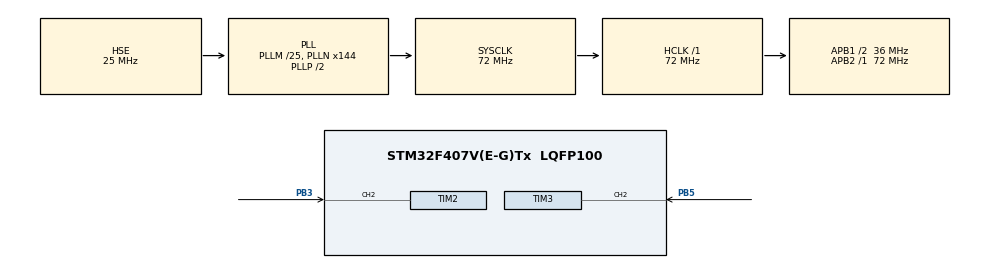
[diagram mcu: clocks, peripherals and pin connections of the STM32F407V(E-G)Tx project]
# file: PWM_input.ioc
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Mcu.Family=STM32F4
Mcu.Name=STM32F407V(E-G)Tx
Mcu.Package=LQFP100
NVIC.PriorityGroup=NVIC_PRIORITYGROUP_4
NVIC.TIM2_IRQn=true\:0\:0\:false\:false\:true\:true\:true
NVIC.TIM3_IRQn=true\:0\:0\:false\:false\:true\:true\:true
PB3.Signal=S_TIM2_CH2
PB5.Signal=S_TIM3_CH2
PH0-OSC_IN.Mode=HSE-External-Oscillator
PH0-OSC_IN.Signal=RCC_OSC_IN
PH1-OSC_OUT.Mode=HSE-External-Oscillator
PH1-OSC_OUT.Signal=RCC_OSC_OUT
ProjectManager.HeapSize=0x200
ProjectManager.StackSize=0x400
ProjectManager.TargetToolchain=MDK-ARM V5.27
RCC.48MHZClocksFreq_Value=36000000
RCC.AHBFreq_Value=72000000
RCC.APB1CLKDivider=RCC_HCLK_DIV2
RCC.APB1Freq_Value=36000000
RCC.APB1TimFreq_Value=72000000
RCC.APB2Freq_Value=72000000
RCC.APB2TimFreq_Value=72000000
RCC.CortexFreq_Value=72000000
RCC.HCLKFreq_Value=72000000
RCC.HSE_VALUE=25000000
RCC.HSI_VALUE=16000000
RCC.LSE_VALUE=32768
RCC.PLLM=25
RCC.PLLN=144
RCC.PLLSourceVirtual=RCC_PLLSOURCE_HSE
RCC.SYSCLKFreq_VALUE=72000000
RCC.SYSCLKSource=RCC_SYSCLKSOURCE_PLLCLK
RCC.VCOOutputFreq_Value=144000000
SH.S_TIM2_CH2.0=TIM2_CH2,Input_Capture2_from_TI2
SH.S_TIM2_CH2.1=TIM2_CH2,Input_Capture1_from_TI2
SH.S_TIM2_CH2.2=TIM2_CH2,TriggerSource_TI2FP2
SH.S_TIM3_CH2.0=TIM3_CH2,Input_Capture2_from_TI2
SH.S_TIM3_CH2.1=TIM3_CH2,Input_Capture1_from_TI2
SH.S_TIM3_CH2.2=TIM3_CH2,TriggerSource_TI2FP2
TIM2.Channel-Input_Capture1_from_TI2=TIM_CHANNEL_1
TIM2.Channel-Input_Capture2_from_TI2=TIM_CHANNEL_2
TIM2.ICPolarity_CH1=TIM_INPUTCHANNELPOLARITY_FALLING
TIM2.Period=0xffff
TIM3.Channel-Input_Capture1_from_TI2=TIM_CHANNEL_1
TIM3.Channel-Input_Capture2_from_TI2=TIM_CHANNEL_2
TIM3.ICPolarity_CH1=TIM_INPUTCHANNELPOLARITY_FALLING
TIM3.Period=0xffff
VP_TIM2_VS_ControllerModeReset.Mode=Reset Mode
VP_TIM3_VS_ControllerModeReset.Mode=Reset Mode
board=custom

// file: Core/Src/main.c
/* USER CODE BEGIN Header */
/**
  ******************************************************************************
  * @file           : main.c
  * @brief          : Main program body
  ******************************************************************************
  * @attention
  *
  * <h2><center>&copy; Copyright (c) 2021 STMicroelectronics.
  * All rights reserved.</center></h2>
  *
  * This software component is licensed by ST under BSD 3-Clause license,
  * the "License"; You may not use this file except in compliance with the
  * License. You may obtain a copy of the License at:
  *                        opensource.org/licenses/BSD-3-Clause
  *
  ******************************************************************************
  */
/* USER CODE END Header */
#include "main.h"
#include "tim.h"
#include "gpio.h"

/* USER CODE BEGIN PV */
uint32_t IC_Val1;
uint32_t IC_Val2;
uint32_t Frequency;
uint32_t Duty_Cycle;
/* USER CODE END PV */

void SystemClock_Config(void);

int main(void)
{

  /* MCU Configuration--------------------------------------------------------*/

  /* Reset of all peripherals, Initializes the Flash interface and the Systick. */
  HAL_Init();

  /* Configure the system clock */
  SystemClock_Config();

  /* Initialize all configured peripherals */
  MX_GPIO_Init();
  MX_TIM2_Init();
  MX_TIM3_Init();
  /* USER CODE BEGIN 2 */
	HAL_TIM_IC_Start_IT(&htim2, TIM_CHANNEL_2);
	HAL_TIM_IC_Start_IT(&htim2, TIM_CHANNEL_1);
	HAL_Delay(1000);
  /* USER CODE END 2 */

  /* Infinite loop */
  while (1)
  {

  }
}

void SystemClock_Config(void)
{
  RCC_OscInitTypeDef RCC_OscInitStruct = {0};
  RCC_ClkInitTypeDef RCC_ClkInitStruct = {0};

  /** Configure the main internal regulator output voltage
  */
  __HAL_RCC_PWR_CLK_ENABLE();
  __HAL_PWR_VOLTAGESCALING_CONFIG(PWR_REGULATOR_VOLTAGE_SCALE1);
  /** Initializes the RCC Oscillators according to the specified parameters
  * in the RCC_OscInitTypeDef structure.
  */
  RCC_OscInitStruct.OscillatorType = RCC_OSCILLATORTYPE_HSE;
  RCC_OscInitStruct.HSEState = RCC_HSE_ON;
  RCC_OscInitStruct.PLL.PLLState = RCC_PLL_ON;
  RCC_OscInitStruct.PLL.PLLSource = RCC_PLLSOURCE_HSE;
  RCC_OscInitStruct.PLL.PLLM = 25;
  RCC_OscInitStruct.PLL.PLLN = 144;
  RCC_OscInitStruct.PLL.PLLP = RCC_PLLP_DIV2;
  RCC_OscInitStruct.PLL.PLLQ = 4;
  if (HAL_RCC_OscConfig(&RCC_OscInitStruct) != HAL_OK)
  {
    Error_Handler();
  }
  /** Initializes the CPU, AHB and APB buses clocks
  */
  RCC_ClkInitStruct.ClockType = RCC_CLOCKTYPE_HCLK|RCC_CLOCKTYPE_SYSCLK
                              |RCC_CLOCKTYPE_PCLK1|RCC_CLOCKTYPE_PCLK2;
  RCC_ClkInitStruct.SYSCLKSource = RCC_SYSCLKSOURCE_PLLCLK;
  RCC_ClkInitStruct.AHBCLKDivider = RCC_SYSCLK_DIV1;
  RCC_ClkInitStruct.APB1CLKDivider = RCC_HCLK_DIV2;
  RCC_ClkInitStruct.APB2CLKDivider = RCC_HCLK_DIV1;

  if (HAL_RCC_ClockConfig(&RCC_ClkInitStruct, FLASH_LATENCY_2) != HAL_OK)
  {
    Error_Handler();
  }
}

/* USER CODE BEGIN 4 */
//Write Input Capture Call Back
void HAL_TIM_IC_CaptureCallback(TIM_HandleTypeDef *htim)
{
	//Rising Edge Interrupt
 if(htim -> Channel == HAL_TIM_ACTIVE_CHANNEL_2)
 {
	 //Read Captured Value
	 //First Value - time period of the pulse
	 IC_Val1 = HAL_TIM_ReadCapturedValue(htim, TIM_CHANNEL_2);

	 if(IC_Val1 != 0)
	 {
		 //Second Vlaue - time for the pulse remain high
		 IC_Val2 = HAL_TIM_ReadCapturedValue(htim, TIM_CHANNEL_1);

		 //Calculate Duty Cycle - set to integer = IC_Val2 / IC_Val1 * 100
		 Duty_Cycle = IC_Val2 * 100 / IC_Val1;

		 //Calculated Frequency - Timer Clock / IC_Val1, which timerclock = 2 * pclk1
		 Frequency = 2 * HAL_RCC_GetPCLK1Freq() / IC_Val1;
	 }
	  else
		{
			Duty_Cycle = 0;
			Frequency = 0;
		}
 }
}
/* USER CODE END 4 */

void Error_Handler(void)
{
  __disable_irq();
  while (1)
  {
  }
}

/************************ (C) COPYRIGHT STMicroelectronics *****END OF FILE****/
